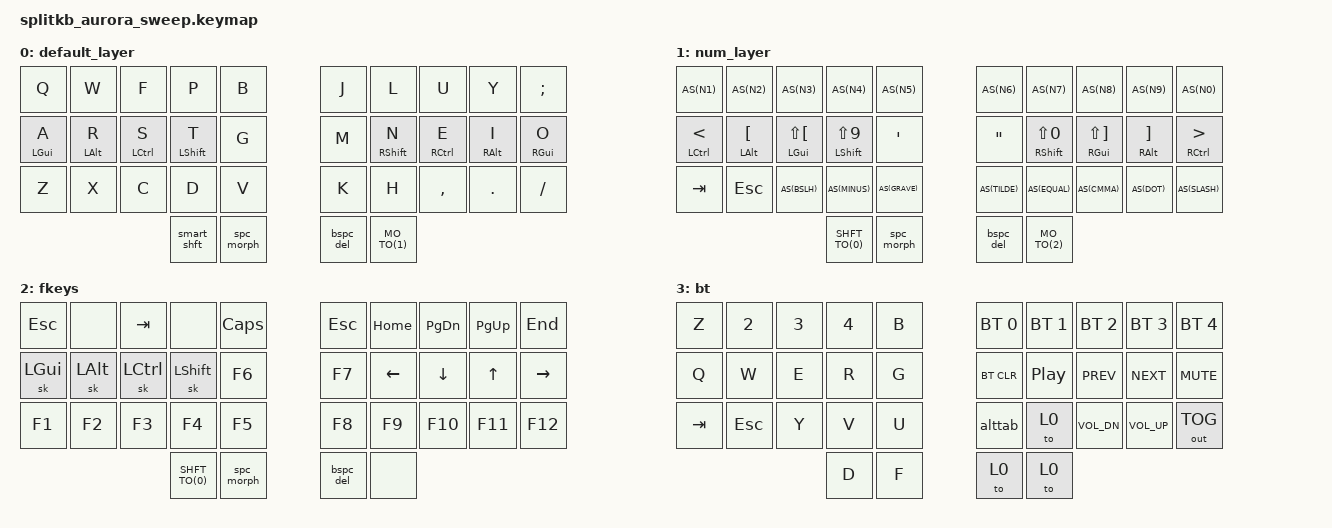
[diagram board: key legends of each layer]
/*
 * Copyright (c) 2022 The ZMK Contributors
 *
 * SPDX-License-Identifier: MIT
 */

#include <behaviors.dtsi>
#include <dt-bindings/zmk/keys.h>
#include <dt-bindings/zmk/bt.h>
#include <dt-bindings/zmk/outputs.h>
#include "zmk-helpers/helper.h"
#include "zmk-helpers/key-labels/34.h"
#include "combos.dtsi"

#define MO_TO(layer) &mo_to layer layer
#define SHFT_TO(layer) &kp_to LSHFT layer
#define AS(keycode) &as LS(keycode) keycode

&caps_word {
    continue-list = <UNDERSCORE MINUS BACKSPACE DEL>;
};

&sk {
    quick-release;
};

/ {

    combos {
        compatible = "zmk,combos";
        combo_del {
            timeout-ms = <150>;
            key-positions = <31 32>;
            bindings = <&kp DEL>;
            layers = <0 1 2>;
        };
    };

    macros {
       alttab: alttab {
            compatible = "zmk,behavior-macro";
            #binding-cells = <0>;
            bindings
                = <&macro_press &kp LALT &kp TAB>
                , <&macro_pause_for_release>
                , <&macro_release &kp LALT &kp TAB>
                ;
        };
        dot_spc: dot_spc {
            compatible = "zmk,behavior-macro";
            #binding-cells = <0>;
            wait-ms = <0>;
            tap-ms = <5>;
            bindings = <&kp DOT &kp SPACE &sk LSHIFT>;
        };
    };

    behaviors {

        lhhm: left_positional_hold_tap {
            compatible = "zmk,behavior-hold-tap";
            #binding-cells = <2>;
            flavor = "balanced";
            tapping-term-ms = <280>;                        // <---[[produces tap if held longer than tapping-term-ms]]
            quick-tap-ms = <175>;
	    require-prior-idle-ms = <150>;
            bindings = <&kp>, <&kp>;
            hold-trigger-key-positions = <5 6 7 8 9 15 16 17 18 19 25 26 27 28 29 32 33>;    // <---[[right-hand keys]]
	    hold-trigger-on-release;
        };

        rhhm: right_positional_hold_tap {
            compatible = "zmk,behavior-hold-tap";
            #binding-cells = <2>;
            flavor = "balanced";
            tapping-term-ms = <280>;                        // <---[[produces tap if held longer than tapping-term-ms]]
            quick-tap-ms = <175>;
	    require-prior-idle-ms = <150>;
            bindings = <&kp>, <&kp>;
            hold-trigger-key-positions = <0 1 2 3 4 10 11 12 13 14 20 21 22 23 24 30 31>;    // <---[[left-hand keys]]
	    hold-trigger-on-release;
        };

        mo_to: behavior_mo_to {
            compatible = "zmk,behavior-hold-tap";
            #binding-cells = <2>;
            flavor = "hold-preferred";
            tapping-term-ms = <200>;
            bindings = <&mo>, <&to>;
        };

        kp_to: behavior_kp_to {
            compatible = "zmk,behavior-hold-tap";
            #binding-cells = <2>;
            flavor = "hold-preferred";
            tapping-term-ms = <200>;
            bindings = <&kp>, <&to>;
        };

        bspc_del: backspace_delete {
            compatible = "zmk,behavior-mod-morph";
            #binding-cells = <0>;
            bindings = <&kp BACKSPACE>, <&kp DELETE>;
            mods = <(MOD_LSFT|MOD_RSFT)>;
            keep-mods = <(MOD_LSFT|MOD_RSFT)>;
        };

        as: auto_shift {
            compatible = "zmk,behavior-hold-tap";
            #binding-cells = <2>;
            tapping_term_ms = <200>;
            quick_tap_ms = <0>;
            flavor = "tap-preferred";
            bindings = <&kp>, <&kp>;
        };

        kp_spc: kp_spc {
            compatible = "zmk,behavior-hold-tap";
            #binding-cells = <2>;
            tapping_term_ms = <200>;
            quick_tap_ms = <175>;
            flavor = "balanced";
            bindings = <&kp>, <&spc_morph>;
        };

        spc_morph: spc_morph {
            compatible = "zmk,behavior-mod-morph";
            #binding-cells = <0>;
            bindings = <&kp SPACE>, <&dot_spc>;
            mods = <(MOD_LSFT|MOD_RSFT)>;
        };

        smart_shft: smart_shft {
            compatible = "zmk,behavior-mod-morph";
            #binding-cells = <0>;
            bindings = <&sk LSHIFT>, <&caps_word>;
            mods = <(MOD_LSFT)>;
        };

    };

    keymap {
        compatible = "zmk,keymap";

        default_layer {
            bindings = <
                &kp Q &kp W &kp F &kp P &kp B                       &kp J &kp L &kp U &kp Y &kp SEMICOLON
                &lhhm LGUI A &lhhm LALT R &lhhm LCTRL S &lhhm LSHFT T &kp G                       &kp M &rhhm RSHFT N &rhhm RCTRL E &rhhm RALT I &rhhm RGUI O
                &kp Z &kp X &kp C &kp D &kp V                       &kp K &kp H  &kp CMMA &kp DOT &kp SLASH
                                &smart_shft &spc_morph            &bspc_del MO_TO(1)
            >;
        };

        num_layer {
            bindings = <
                AS(N1) AS(N2) AS(N3) AS(N4) AS(N5)              AS(N6) AS(N7) AS(N8) AS(N9) AS(N0)
                &lhhm LCTRL LT &lhhm LALT LBKT &lhhm LGUI LS(LBKT) &lhhm LSHFT LS(N9) &kp SQT                       &kp DQT &rhhm RSHFT LS(N0) &rhhm RGUI LS(RBKT) &rhhm RALT RBKT &rhhm RCTRL GT
                &kp TAB &kp ESC AS(BSLH) AS(MINUS) AS(GRAVE)          AS(TILDE) AS(EQUAL) AS(CMMA) AS(DOT) AS(SLASH)
                SHFT_TO(0)  &spc_morph                             &bspc_del MO_TO(2) 
            >;
        };

        fkeys {
            bindings = <
                &kp ESC &none &kp TAB &none &kp CAPSLOCK                     &kp ESC &kp HOME &kp PAGE_DOWN &kp PAGE_UP &kp END
                &sk LGUI &sk LALT &sk LCTRL &sk LSHFT &kp F6                 &kp F7 &kp LEFT &kp DOWN &kp UP &kp RIGHT
                &kp F1 &kp F2 &kp F3 &kp F4 &kp F5                           &kp F8 &kp F9 &kp F10 &kp F11 &kp F12
                SHFT_TO(0) &spc_morph                             &bspc_del &none
            >;
        };

        bt {
            bindings = <
                &kp Z  &kp N2 &kp N3 &kp N4 &kp B       &bt BT_SEL 0 &bt BT_SEL 1 &bt BT_SEL 2 &bt BT_SEL 3 &bt BT_SEL 4
                &kp Q  &kp W &kp E &kp R &kp G       &bt BT_CLR &kp C_PP &kp C_PREV &kp C_NEXT &kp C_MUTE
                &kp TAB  &kp ESC &kp Y &kp V &kp U       &alttab &to 0 &kp C_VOL_DN &kp C_VOL_UP &out OUT_TOG
                &kp D &kp F  					                            &to 0 &to 0
            >;
        };

    };
};
